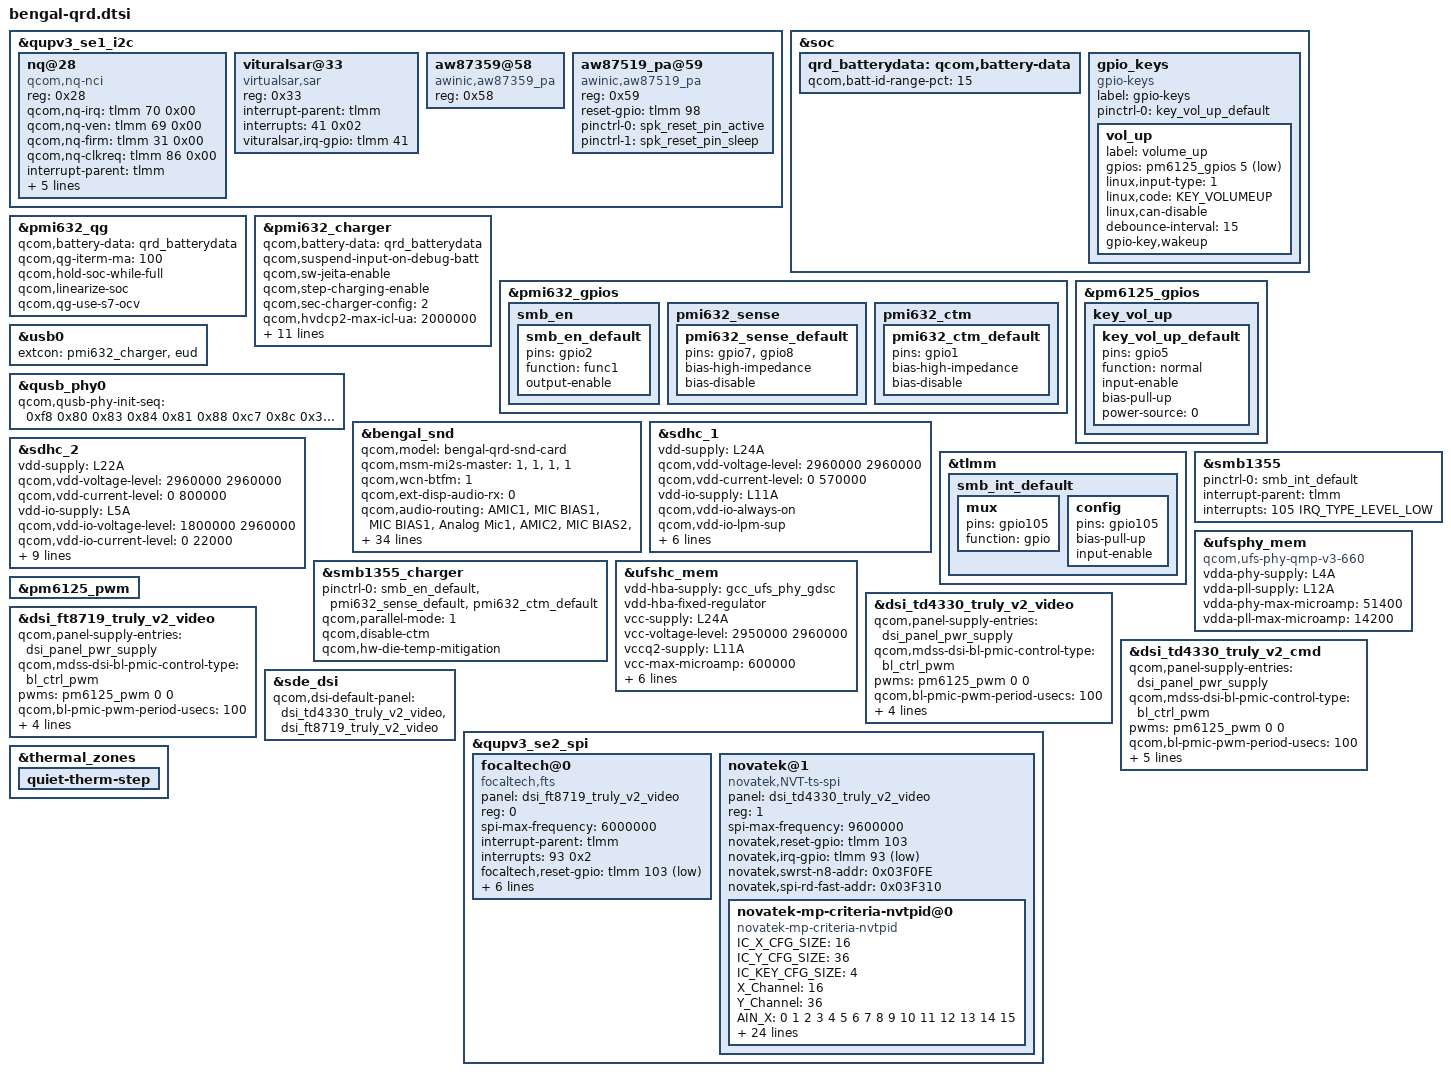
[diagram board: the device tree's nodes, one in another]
#include <dt-bindings/gpio/gpio.h>
#include <dt-bindings/iio/qcom,spmi-vadc.h>
#include <dt-bindings/input/input.h>
#include "bengal-thermal-overlay.dtsi"
#include "bengal-audio-overlay.dtsi"
#include "bengal-sde-display.dtsi"
#include "camera/bengal-camera-sensor-qrd.dtsi"

&qupv3_se1_i2c {
	status = "ok";
	#include "smb1355.dtsi"
};

&soc {
	qrd_batterydata: qcom,battery-data {
		qcom,batt-id-range-pct = <15>;
		#include "qg-batterydata-atl466271_3300mAh.dtsi"
	};
};

&pmi632_qg {
	qcom,battery-data = <&qrd_batterydata>;
	qcom,qg-iterm-ma = <100>;
	qcom,hold-soc-while-full;
	qcom,linearize-soc;
	qcom,qg-use-s7-ocv;
};

&pmi632_charger {
	qcom,battery-data = <&qrd_batterydata>;
	qcom,suspend-input-on-debug-batt;
	qcom,sw-jeita-enable;
	qcom,step-charging-enable;
	/* SMB1355 only */
	qcom,sec-charger-config = <2>;
	qcom,hvdcp2-max-icl-ua = <2000000>;
	dpdm-supply = <&qusb_phy0>;
	qcom,charger-temp-max = <800>;
	qcom,smb-temp-max = <800>;
	qcom,auto-recharge-soc = <98>;
	qcom,flash-disable-soc = <1>;
	qcom,hw-die-temp-mitigation;
	qcom,hw-connector-mitigation;
	qcom,connector-internal-pull-kohm = <100>;
	qcom,float-option = <1>;
	qcom,thermal-mitigation = <4200000 3500000 3000000
			2500000 2000000 1500000 1000000 500000>;
};

&pmi632_gpios {
	smb_en {
		smb_en_default: smb_en_default {
			pins = "gpio2";
			function = "func1";
			output-enable;
		};
	};

	pmi632_sense {
		/* GPIO 7 and 8 are external-sense pins for PMI632 */
		pmi632_sense_default: pmi632_sense_default {
			pins = "gpio7", "gpio8";
			bias-high-impedance;	/* disable the GPIO */
			bias-disable;		/* no-pull */
		};
	};

	pmi632_ctm {
		/* Disable GPIO1 for h/w base mitigation */
		pmi632_ctm_default: pmi632_ctm_default {
			pins = "gpio1";
			bias-high-impedance;	/* disable the GPIO */
			bias-disable;		/* no-pull */
		};
	};
};

&pm6125_gpios {
	key_vol_up {
		key_vol_up_default: key_vol_up_default {
			pins = "gpio5";
			function = "normal";
			input-enable;
			bias-pull-up;
			power-source = <0>;
		};
	};
};

&usb0 {
	extcon = <&pmi632_charger>, <&eud>;
};

&qusb_phy0 {
	qcom,qusb-phy-init-seq = <0xf8 0x80
				0x83 0x84
				0x81 0x88
				0xc7 0x8c
				0x30 0x08
				0x79 0x0c
				0x21 0x10
				0x14 0x9c
				0x80 0x04
				0x9f 0x1c
				0x00 0x18>;
};

&soc {
	gpio_keys {
		compatible = "gpio-keys";
		label = "gpio-keys";

		pinctrl-names = "default";
		pinctrl-0 = <&key_vol_up_default>;

		vol_up {
			label = "volume_up";
			gpios = <&pm6125_gpios 5 GPIO_ACTIVE_LOW>;
			linux,input-type = <1>;
			linux,code = <KEY_VOLUMEUP>;
			linux,can-disable;
			debounce-interval = <15>;
			gpio-key,wakeup;
		};
	};
};

&bengal_snd {
	qcom,model = "bengal-qrd-snd-card";
	qcom,msm-mi2s-master = <1>, <1>, <1>, <1>;
	qcom,wcn-btfm = <1>;
	qcom,ext-disp-audio-rx = <0>;
	qcom,audio-routing =
		"AMIC1", "MIC BIAS1",
		"MIC BIAS1", "Analog Mic1",
		"AMIC2", "MIC BIAS2",
		"MIC BIAS2", "Analog Mic2",
		"AMIC3", "MIC BIAS3",
		"MIC BIAS3", "Analog Mic3",
		"AMIC4", "MIC BIAS3",
		"MIC BIAS3", "Analog Mic4",
		"IN1_HPHL", "HPHL_OUT",
		"IN2_HPHR", "HPHR_OUT",
		"IN3_AUX", "AUX_OUT",
		"SpkrMono WSA_IN", "AUX",
		"TX SWR_MIC0", "ADC1_OUTPUT",
		"TX SWR_MIC4", "ADC2_OUTPUT",
		"TX SWR_MIC5", "ADC3_OUTPUT",
		"TX SWR_MIC0", "VA_TX_SWR_CLK",
		"TX SWR_MIC1", "VA_TX_SWR_CLK",
		"TX SWR_MIC2", "VA_TX_SWR_CLK",
		"TX SWR_MIC3", "VA_TX_SWR_CLK",
		"TX SWR_MIC4", "VA_TX_SWR_CLK",
		"TX SWR_MIC5", "VA_TX_SWR_CLK",
		"TX SWR_MIC6", "VA_TX_SWR_CLK",
		"TX SWR_MIC7", "VA_TX_SWR_CLK",
		"TX SWR_MIC8", "VA_TX_SWR_CLK",
		"TX SWR_MIC9", "VA_TX_SWR_CLK",
		"TX SWR_MIC10", "VA_TX_SWR_CLK",
		"TX SWR_MIC11", "VA_TX_SWR_CLK",
		"RX_TX DEC0_INP", "TX DEC0 MUX",
		"RX_TX DEC1_INP", "TX DEC1 MUX",
		"RX_TX DEC2_INP", "TX DEC2 MUX",
		"RX_TX DEC3_INP", "TX DEC3 MUX",
		"TX_AIF1 CAP", "VA_TX_SWR_CLK",
		"TX_AIF2 CAP", "VA_TX_SWR_CLK",
		"TX_AIF3 CAP", "VA_TX_SWR_CLK",
		"VA SWR_MIC0", "ADC1_OUTPUT",
		"VA SWR_MIC4", "ADC2_OUTPUT",
		"VA SWR_MIC5", "ADC3_OUTPUT";
	qcom,msm-mbhc-hphl-swh = <1>;
	qcom,msm-mbhc-gnd-swh = <1>;
	asoc-codec  = <&stub_codec>, <&bolero>;
	asoc-codec-names = "msm-stub-codec.1", "bolero_codec";
	qcom,wsa-max-devs = <0>;
	qcom,wsa-devs = <0>;
	qcom,wsa-aux-dev-prefix = "SpkrMono";
	qcom,codec-max-aux-devs = <1>;
	qcom,codec-aux-devs = <&wcd937x_codec>;
	qcom,msm_audio_ssr_devs = <&audio_apr>, <&q6core>, <&bolero>,
				<&lpi_tlmm>;
};

&qupv3_se1_i2c {
	status = "ok";
	#address-cells = <1>;
	#size-cells = <0>;
	nq@28 {
		compatible = "qcom,nq-nci";
		reg = <0x28>;
		qcom,nq-irq = <&tlmm 70 0x00>;
		qcom,nq-ven = <&tlmm 69 0x00>;
		qcom,nq-firm = <&tlmm 31 0x00>;
		qcom,nq-clkreq = <&tlmm 86 0x00>;
		interrupt-parent = <&tlmm>;
		interrupts = <70 0>;
		interrupt-names = "nfc_irq";
		pinctrl-names = "nfc_active", "nfc_suspend";
		pinctrl-0 = <&nfc_int_active &nfc_enable_active
				&nfc_clk_req_active>;
		pinctrl-1 = <&nfc_int_suspend &nfc_enable_suspend
				&nfc_clk_req_suspend>;
	};

	vituralsar@33{/*Add by HQ-102007757 for vituralsar*/
		compatible = "virtualsar,sar";
		reg = <0x33>;
		interrupt-parent = <&tlmm>;
		interrupts = <41 0x02>;
		vituralsar,irq-gpio = <&tlmm 41 0x2008>;
		status = "ok";
	};

	aw87359@58 {
		compatible = "awinic,aw87359_pa";
		reg = <0x58>;
		status = "okay";
	};

	aw87519_pa@59 {
		compatible = "awinic,aw87519_pa";
		reg = <0x59>;
		reset-gpio = <&tlmm 98 0>;
		pinctrl-names = "aw87519_pa_reset_active", "aw87519_pa_reset_sleep";
		pinctrl-0 = <&spk_reset_pin_active>;
		pinctrl-1 = <&spk_reset_pin_sleep>;
	};
};

&sdhc_1 {
	vdd-supply = <&L24A>;
	qcom,vdd-voltage-level = <2960000 2960000>;
	qcom,vdd-current-level = <0 570000>;

	vdd-io-supply = <&L11A>;
	qcom,vdd-io-always-on;
	qcom,vdd-io-lpm-sup;
	qcom,vdd-io-voltage-level = <1800000 1800000>;
	qcom,vdd-io-current-level = <0 325000>;

	pinctrl-names = "active", "sleep";
	pinctrl-0 = <&sdc1_clk_on &sdc1_cmd_on &sdc1_data_on
					&sdc1_rclk_on>;
	pinctrl-1 = <&sdc1_clk_off &sdc1_cmd_off &sdc1_data_off
					&sdc1_rclk_off>;

	status = "ok";
};

&sdhc_2 {
	vdd-supply = <&L22A>;
	qcom,vdd-voltage-level = <2960000 2960000>;
	qcom,vdd-current-level = <0 800000>;

	vdd-io-supply = <&L5A>;
	qcom,vdd-io-voltage-level = <1800000 2960000>;
	qcom,vdd-io-current-level = <0 22000>;

	vdd-io-bias-supply = <&L7A>;
	qcom,vdd-io-bias-voltage-level = <1256000 1256000>;
	qcom,vdd-io-bias-current-level = <0 6000>;

	pinctrl-names = "active", "sleep";
	pinctrl-0 = <&sdc2_clk_on  &sdc2_cmd_on &sdc2_data_on &sdc2_cd_on>;
	pinctrl-1 = <&sdc2_clk_off &sdc2_cmd_off &sdc2_data_off &sdc2_cd_off>;

	cd-gpios = <&tlmm 88 GPIO_ACTIVE_HIGH>;

	status = "ok";
};

&tlmm {
	smb_int_default: smb_int_default {
		mux {
			pins = "gpio105";
			function = "gpio";
		};

		config {
			pins = "gpio105";
			bias-pull-up;
			input-enable;
		};
	};
};

&smb1355 {
	pinctrl-names = "default";
	pinctrl-0 = <&smb_int_default>;
	interrupt-parent = <&tlmm>;
	interrupts = <105 IRQ_TYPE_LEVEL_LOW>;
	status = "ok";
};

&smb1355_charger {
	pinctrl-names = "default";
	pinctrl-0 = <&smb_en_default &pmi632_sense_default &pmi632_ctm_default>;
	qcom,parallel-mode = <1>;
	qcom,disable-ctm;
	qcom,hw-die-temp-mitigation;
	status = "ok";
};

&ufsphy_mem {
	compatible = "qcom,ufs-phy-qmp-v3-660";

	vdda-phy-supply = <&L4A>; /* 0.9v */
	vdda-pll-supply = <&L12A>; /* 1.8v */
	vdda-phy-max-microamp = <51400>;
	vdda-pll-max-microamp = <14200>;

	status = "ok";
};

&ufshc_mem {
	vdd-hba-supply = <&gcc_ufs_phy_gdsc>;
	vdd-hba-fixed-regulator;
	vcc-supply = <&L24A>;
	vcc-voltage-level = <2950000 2960000>;
	vccq2-supply = <&L11A>;
	vcc-max-microamp = <600000>;
	vccq2-max-microamp = <600000>;
	vccq2-pwr-collapse-sup;

	qcom,vddp-ref-clk-supply = <&L18A>;
	qcom,vddp-ref-clk-max-microamp = <100>;
	qcom,vddp-ref-clk-min-uV = <1232000>;
	qcom,vddp-ref-clk-max-uV = <1232000>;

	status = "ok";
};

&pm6125_pwm {
	status = "ok";
};

&dsi_td4330_truly_v2_video {
	qcom,panel-supply-entries = <&dsi_panel_pwr_supply>;
	qcom,mdss-dsi-bl-pmic-control-type = "bl_ctrl_pwm";
	pwms = <&pm6125_pwm 0 0>;
	qcom,bl-pmic-pwm-period-usecs = <100>;
	qcom,mdss-dsi-bl-min-level = <1>;
	qcom,mdss-dsi-bl-max-level = <4095>;
	qcom,platform-reset-gpio = <&tlmm 82 0>;
	qcom,platform-bklight-en-gpio = <&pmi632_gpios 6 0>;
};


&dsi_ft8719_truly_v2_video {
	qcom,panel-supply-entries = <&dsi_panel_pwr_supply>;
	qcom,mdss-dsi-bl-pmic-control-type = "bl_ctrl_pwm";
	pwms = <&pm6125_pwm 0 0>;
	qcom,bl-pmic-pwm-period-usecs = <100>;
	qcom,mdss-dsi-bl-min-level = <1>;
	qcom,mdss-dsi-bl-max-level = <4095>;
	qcom,platform-reset-gpio = <&tlmm 82 0>;
	qcom,platform-bklight-en-gpio = <&pmi632_gpios 6 0>;
};

&dsi_td4330_truly_v2_cmd {
	qcom,panel-supply-entries = <&dsi_panel_pwr_supply>;
	qcom,mdss-dsi-bl-pmic-control-type = "bl_ctrl_pwm";
	pwms = <&pm6125_pwm 0 0>;
	qcom,bl-pmic-pwm-period-usecs = <100>;
	qcom,mdss-dsi-bl-min-level = <1>;
	qcom,mdss-dsi-bl-max-level = <4095>;
	qcom,platform-te-gpio = <&tlmm 81 0>;
	qcom,platform-reset-gpio = <&tlmm 82 0>;
	qcom,platform-bklight-en-gpio = <&pmi632_gpios 6 0>;
};

&sde_dsi {
	qcom,dsi-default-panel = <&dsi_td4330_truly_v2_video &dsi_ft8719_truly_v2_video>;
};
/*
&qupv3_se2_i2c {
	status = "okay";
	qcom,i2c-touch-active="synaptics,tcm-i2c";

	synaptics_tcm@20 {
		compatible = "synaptics,tcm-i2c";
		reg = <0x20>;
		interrupt-parent = <&tlmm>;
		interrupts = <80 0x2008>;
		pinctrl-names = "pmx_ts_active","pmx_ts_suspend",
			"pmx_ts_release";
		pinctrl-0 = <&ts_int_active &ts_reset_active>;
		pinctrl-1 = <&ts_int_suspend &ts_reset_suspend>;
		pinctrl-2 = <&ts_release>;
		synaptics,irq-gpio = <&tlmm 80 0x2008>;
		synaptics,irq-on-state = <0>;
		synaptics,reset-gpio = <&tlmm 71 0x00>;
		synaptics,reset-on-state = <0>;
		synaptics,reset-active-ms = <20>;
		synaptics,reset-delay-ms = <200>;
		synaptics,power-delay-ms = <200>;
		synaptics,ubl-i2c-addr = <0x20>;
		synaptics,extend_report;
		synaptics,firmware-name = "synaptics_firmware_k.img";

		panel = <&dsi_td4330_truly_v2_video &dsi_td4330_truly_v2_cmd>;
	};
};*/


&qupv3_se2_spi {
	status = "okay";
	focaltech@0 { 
			compatible = "focaltech,fts";
			panel = <&dsi_ft8719_truly_v2_video>;
			reg = <0>;
			spi-max-frequency = <6000000>;
			interrupt-parent = <&tlmm>;
			interrupts = <93 0x2>;
			focaltech,reset-gpio = <&tlmm 103 0x01>;
			focaltech,irq-gpio = <&tlmm 93 0x02>;
			focaltech,max-touch-number = <10>;			
			focaltech,display-coords =  <0 0 1080 2340>;
			
			pinctrl-names = "pmx_ts_active","pmx_ts_suspend","pmx_ts_release";
			pinctrl-0 = <&ts_int_active &ts_reset_active>;
			pinctrl-1 = <&ts_int_suspend &ts_reset_suspend>;
			pinctrl-2 = <&ts_release>;
		};


	/* Novatek device tree node */
	novatek@1 {
		compatible = "novatek,NVT-ts-spi";
		panel = <&dsi_td4330_truly_v2_video>;
		reg = <1>; //Same as CS ID
		status = "ok";

		spi-max-frequency = <9600000>;	//4800000,9600000,15000000,19200000
		novatek,reset-gpio = <&tlmm 103 0x00>;
		novatek,irq-gpio = <&tlmm 93 0x2001>;

		/* 525 */
		//novatek,swrst-n8-addr = <0x01F01A>;

		/* 672A, 525B, 675, 526, 672C */
		novatek,swrst-n8-addr = <0x03F0FE>;
		novatek,spi-rd-fast-addr = <0x03F310>;

		/* MP */
		//novatek,mp-support-dt;

		novatek-mp-criteria-nvtpid@0 {
			#address-cells = <1>;
			#size-cells = <0>;
			compatible = "novatek-mp-criteria-nvtpid";

			/* MP Config */
			IC_X_CFG_SIZE = <16>;
			IC_Y_CFG_SIZE = <36>;
			IC_KEY_CFG_SIZE = <4>;
			X_Channel = <16>;
			Y_Channel = <36>;
			AIN_X = <0 1 2 3 4 5 6 7 8 9 10 11 12 13 14 15>;
			AIN_Y = <0 1 2 3 4 5 6 7 8 9 10 11 12 13 14 15 16 17
						18 19 20 21 22 23 24 25 26 27 28 29 30 31 32 33 34 35>;
			AIN_KEY = <0 1 2 0xFF>;

			/* MP Criteria */
			PS_Config_Lmt_Short_Rawdata_P = <
				14000	14000	14000	14000	14000	14000	14000	14000	14000	14000	14000	14000	14000	14000	14000	14000
				14000	14000	14000	14000	14000	14000	14000	14000	14000	14000	14000	14000	14000	14000	14000	14000
				14000	14000	14000	14000	14000	14000	14000	14000	14000	14000	14000	14000	14000	14000	14000	14000
				14000	14000	14000	14000	14000	14000	14000	14000	14000	14000	14000	14000	14000	14000	14000	14000
				14000	14000	14000	14000	14000	14000	14000	14000	14000	14000	14000	14000	14000	14000	14000	14000
				14000	14000	14000	14000	14000	14000	14000	14000	14000	14000	14000	14000	14000	14000	14000	14000
				14000	14000	14000	14000	14000	14000	14000	14000	14000	14000	14000	14000	14000	14000	14000	14000
				14000	14000	14000	14000	14000	14000	14000	14000	14000	14000	14000	14000	14000	14000	14000	14000
				14000	14000	14000	14000	14000	14000	14000	14000	14000	14000	14000	14000	14000	14000	14000	14000
				14000	14000	14000	14000	14000	14000	14000	14000	14000	14000	14000	14000	14000	14000	14000	14000
				14000	14000	14000	14000	14000	14000	14000	14000	14000	14000	14000	14000	14000	14000	14000	14000
				14000	14000	14000	14000	14000	14000	14000	14000	14000	14000	14000	14000	14000	14000	14000	14000
				14000	14000	14000	14000	14000	14000	14000	14000	14000	14000	14000	14000	14000	14000	14000	14000
				14000	14000	14000	14000	14000	14000	14000	14000	14000	14000	14000	14000	14000	14000	14000	14000
				14000	14000	14000	14000	14000	14000	14000	14000	14000	14000	14000	14000	14000	14000	14000	14000
				14000	14000	14000	14000	14000	14000	14000	14000	14000	14000	14000	14000	14000	14000	14000	14000
				14000	14000	14000	14000	14000	14000	14000	14000	14000	14000	14000	14000	14000	14000	14000	14000
				14000	14000	14000	14000	14000	14000	14000	14000	14000	14000	14000	14000	14000	14000	14000	14000
				14000	14000	14000	14000	14000	14000	14000	14000	14000	14000	14000	14000	14000	14000	14000	14000
				14000	14000	14000	14000	14000	14000	14000	14000	14000	14000	14000	14000	14000	14000	14000	14000
				14000	14000	14000	14000	14000	14000	14000	14000	14000	14000	14000	14000	14000	14000	14000	14000
				14000	14000	14000	14000	14000	14000	14000	14000	14000	14000	14000	14000	14000	14000	14000	14000
				14000	14000	14000	14000	14000	14000	14000	14000	14000	14000	14000	14000	14000	14000	14000	14000
				14000	14000	14000	14000	14000	14000	14000	14000	14000	14000	14000	14000	14000	14000	14000	14000
				14000	14000	14000	14000	14000	14000	14000	14000	14000	14000	14000	14000	14000	14000	14000	14000
				14000	14000	14000	14000	14000	14000	14000	14000	14000	14000	14000	14000	14000	14000	14000	14000
				14000	14000	14000	14000	14000	14000	14000	14000	14000	14000	14000	14000	14000	14000	14000	14000
				14000	14000	14000	14000	14000	14000	14000	14000	14000	14000	14000	14000	14000	14000	14000	14000
				14000	14000	14000	14000	14000	14000	14000	14000	14000	14000	14000	14000	14000	14000	14000	14000
				14000	14000	14000	14000	14000	14000	14000	14000	14000	14000	14000	14000	14000	14000	14000	14000
				14000	14000	14000	14000	14000	14000	14000	14000	14000	14000	14000	14000	14000	14000	14000	14000
				14000	14000	14000	14000	14000	14000	14000	14000	14000	14000	14000	14000	14000	14000	14000	14000
				14000	14000	14000	14000	14000	14000	14000	14000	14000	14000	14000	14000	14000	14000	14000	14000
				14000	14000	14000	14000	14000	14000	14000	14000	14000	14000	14000	14000	14000	14000	14000	14000
				14000	14000	14000	14000	14000	14000	14000	14000	14000	14000	14000	14000	14000	14000	14000	14000
				14000	14000	14000	14000	14000	14000	14000	14000	14000	14000	14000	14000	14000	14000	14000	14000
				14008 14008 14008>;

			PS_Config_Lmt_Short_Rawdata_N = <
				11300	11300	11300	11300	11300	11300	11300	11300	11300	11300	11300	11300	11300	11300	11300	11300
				11300	11300	11300	11300	11300	11300	11300	11300	11300	11300	11300	11300	11300	11300	11300	11300
				11300	11300	11300	11300	11300	11300	11300	11300	11300	11300	11300	11300	11300	11300	11300	11300
				11300	11300	11300	11300	11300	11300	11300	11300	11300	11300	11300	11300	11300	11300	11300	11300
				11300	11300	11300	11300	11300	11300	11300	11300	11300	11300	11300	11300	11300	11300	11300	11300
				11300	11300	11300	11300	11300	11300	11300	11300	11300	11300	11300	11300	11300	11300	11300	11300
				11300	11300	11300	11300	11300	11300	11300	11300	11300	11300	11300	11300	11300	11300	11300	11300
				11300	11300	11300	11300	11300	11300	11300	11300	11300	11300	11300	11300	11300	11300	11300	11300
				11300	11300	11300	11300	11300	11300	11300	11300	11300	11300	11300	11300	11300	11300	11300	11300
				11300	11300	11300	11300	11300	11300	11300	11300	11300	11300	11300	11300	11300	11300	11300	11300
				11300	11300	11300	11300	11300	11300	11300	11300	11300	11300	11300	11300	11300	11300	11300	11300
				11300	11300	11300	11300	11300	11300	11300	11300	11300	11300	11300	11300	11300	11300	11300	11300
				11300	11300	11300	11300	11300	11300	11300	11300	11300	11300	11300	11300	11300	11300	11300	11300
				11300	11300	11300	11300	11300	11300	11300	11300	11300	11300	11300	11300	11300	11300	11300	11300
				11300	11300	11300	11300	11300	11300	11300	11300	11300	11300	11300	11300	11300	11300	11300	11300
				11300	11300	11300	11300	11300	11300	11300	11300	11300	11300	11300	11300	11300	11300	11300	11300
				11300	11300	11300	11300	11300	11300	11300	11300	11300	11300	11300	11300	11300	11300	11300	11300
				11300	11300	11300	11300	11300	11300	11300	11300	11300	11300	11300	11300	11300	11300	11300	11300
				11300	11300	11300	11300	11300	11300	11300	11300	11300	11300	11300	11300	11300	11300	11300	11300
				11300	11300	11300	11300	11300	11300	11300	11300	11300	11300	11300	11300	11300	11300	11300	11300
				11300	11300	11300	11300	11300	11300	11300	11300	11300	11300	11300	11300	11300	11300	11300	11300
				11300	11300	11300	11300	11300	11300	11300	11300	11300	11300	11300	11300	11300	11300	11300	11300
				11300	11300	11300	11300	11300	11300	11300	11300	11300	11300	11300	11300	11300	11300	11300	11300
				11300	11300	11300	11300	11300	11300	11300	11300	11300	11300	11300	11300	11300	11300	11300	11300
				11300	11300	11300	11300	11300	11300	11300	11300	11300	11300	11300	11300	11300	11300	11300	11300
				11300	11300	11300	11300	11300	11300	11300	11300	11300	11300	11300	11300	11300	11300	11300	11300
				11300	11300	11300	11300	11300	11300	11300	11300	11300	11300	11300	11300	11300	11300	11300	11300
				11300	11300	11300	11300	11300	11300	11300	11300	11300	11300	11300	11300	11300	11300	11300	11300
				11300	11300	11300	11300	11300	11300	11300	11300	11300	11300	11300	11300	11300	11300	11300	11300
				11300	11300	11300	11300	11300	11300	11300	11300	11300	11300	11300	11300	11300	11300	11300	11300
				11300	11300	11300	11300	11300	11300	11300	11300	11300	11300	11300	11300	11300	11300	11300	11300
				11300	11300	11300	11300	11300	11300	11300	11300	11300	11300	11300	11300	11300	11300	11300	11300
				11300	11300	11300	11300	11300	11300	11300	11300	11300	11300	11300	11300	11300	11300	11300	11300
				11300	11300	11300	11300	11300	11300	11300	11300	11300	11300	11300	11300	11300	11300	11300	11300
				11300	11300	11300	11300	11300	11300	11300	11300	11300	11300	11300	11300	11300	11300	11300	11300
				11300	11300	11300	11300	11300	11300	11300	11300	11300	11300	11300	11300	11300	11300	11300	11300
				10000 10000 10000>;

			PS_Config_Lmt_Open_Rawdata_P = <
				2712	4204	4217	4272	4224	4255	3641	65535	65535	3700	4265	4324	4292	4372	4271	2824
				4152	4251	4193	4249	4201	4235	4185	4338	4290	4279	4240	4288	4260	4337	4307	4304
				4262	4276	4216	4271	4220	4259	4206	4232	4227	4298	4258	4306	4282	4356	4321	4371
				4241	4288	4231	4286	4230	4273	4217	4244	4245	4312	4277	4323	4302	4371	4338	4372
				4263	4274	4221	4276	4217	4258	4202	4227	4235	4305	4272	4316	4297	4366	4329	4382
				4269	4300	4248	4298	4239	4282	4222	4249	4244	4311	4282	4324	4305	4371	4335	4373
				4255	4304	4250	4300	4243	4284	4222	4249	4258	4320	4293	4337	4312	4378	4345	4377
				4274	4319	4263	4310	4250	4297	4234	4259	4251	4311	4286	4334	4309	4372	4339	4386
				4278	4311	4259	4305	4246	4291	4227	4253	4262	4320	4297	4342	4316	4378	4347	4377
				4287	4330	4276	4324	4267	4311	4244	4273	4284	4331	4295	4358	4329	4389	4358	4380
				4276	4316	4264	4307	4248	4295	4227	4260	4283	4331	4295	4358	4333	4391	4356	4389
				4290	4319	4268	4310	4250	4296	4229	4260	4284	4330	4296	4358	4329	4389	4352	4385
				4272	4324	4273	4314	4255	4302	4235	4265	4293	4340	4307	4370	4338	4399	4361	4373
				4269	4325	4277	4318	4262	4307	4237	4277	4291	4339	4309	4371	4335	4394	4354	4394
				4269	4318	4278	4318	4257	4302	4235	4279	4287	4335	4301	4361	4326	4386	4343	4390
				4272	4312	4269	4309	4248	4295	4232	4274	4312	4358	4325	4384	4345	4408	4361	4358
				4268	4300	4258	4300	4240	4286	4222	4278	4307	4358	4325	4385	4347	4409	4357	4366
				4258	4301	4260	4300	4239	4283	4220	4272	4278	4324	4293	4353	4314	4376	4324	4367
				4245	4302	4258	4297	4237	4283	4222	4276	4282	4329	4300	4361	4319	4378	4328	4351
				4237	4287	4241	4283	4224	4272	4211	4262	4283	4326	4298	4357	4312	4371	4318	4354
				4236	4282	4234	4277	4216	4264	4204	4254	4260	4311	4279	4338	4296	4354	4296	4364
				4222	4284	4236	4278	4217	4268	4211	4258	4263	4318	4284	4343	4298	4358	4298	4345
				4215	4264	4217	4258	4196	4245	4189	4239	4271	4328	4292	4349	4302	4363	4310	4323
				4220	4260	4212	4254	4191	4240	4185	4239	4250	4311	4273	4328	4283	4344	4291	4306
				4198	4240	4193	4240	4177	4229	4173	4224	4235	4295	4254	4309	4263	4320	4267	4306
				4197	4230	4183	4229	4165	4216	4164	4212	4222	4282	4243	4297	4251	4306	4254	4297
				4175	4221	4169	4212	4152	4207	4156	4208	4213	4279	4235	4288	4245	4298	4249	4271
				4165	4208	4157	4202	4141	4199	4142	4194	4207	4272	4227	4281	4237	4290	4237	4263
				4155	4194	4142	4187	4126	4182	4128	4180	4180	4243	4197	4249	4207	4259	4211	4251
				4144	4175	4124	4170	4109	4168	4113	4164	4169	4232	4185	4240	4199	4250	4203	4232
				4130	4156	4103	4147	4090	4146	4093	4145	4156	4218	4170	4224	4183	4236	4191	4211
				3803	4146	3787	4137	3776	4137	3782	4136	3829	4202	3841	4210	3854	4217	3859	4203
				3787	3827	3775	3821	3761	3813	3766	3818	3808	3864	3821	3877	3836	3887	3845	3897
				3778	3811	3763	3807	3749	3801	3757	3808	3802	3856	3813	3870	3830	3881	3840	3915
				3677	3771	3722	3770	3712	3764	3719	3771	3782	3834	3792	3849	3808	3859	3818	3796
				2246	3721	3733	3785	3728	3778	3733	3788	3787	3836	3794	3855	3815	3865	3765	2343
				5120 5120 5120>;

			PS_Config_Lmt_Open_Rawdata_N = <
				1559	2417	2424	2455	2427	2446	2092	(-65535)	(-65535)	2127	2452	2485	2467	2513	2454	1623
				2387	2444	2410	2442	2414	2434	2406	2493	2465	2460	2437	2465	2449	2492	2476	2473
				2449	2457	2423	2454	2425	2448	2417	2433	2430	2471	2447	2475	2461	2503	2484	2512
				2438	2465	2432	2463	2431	2456	2424	2439	2440	2479	2458	2484	2473	2512	2493	2513
				2450	2457	2426	2457	2424	2447	2415	2430	2434	2474	2455	2481	2470	2509	2488	2519
				2454	2471	2441	2471	2436	2461	2427	2442	2439	2478	2461	2485	2474	2512	2492	2514
				2446	2473	2443	2471	2438	2463	2427	2442	2447	2483	2468	2492	2479	2517	2498	2516
				2457	2482	2450	2477	2443	2470	2433	2448	2444	2478	2463	2491	2476	2513	2494	2521
				2459	2478	2448	2474	2441	2466	2430	2444	2449	2483	2470	2495	2481	2517	2498	2516
				2464	2489	2457	2485	2452	2478	2439	2456	2463	2490	2468	2505	2488	2522	2505	2517
				2457	2481	2451	2476	2441	2468	2430	2449	2462	2490	2468	2505	2490	2524	2503	2522
				2465	2482	2453	2477	2443	2469	2430	2449	2463	2489	2469	2505	2488	2522	2501	2520
				2455	2485	2456	2479	2446	2473	2434	2452	2468	2495	2476	2511	2493	2528	2506	2514
				2454	2486	2458	2482	2449	2476	2436	2458	2466	2494	2476	2512	2492	2525	2503	2525
				2454	2482	2459	2482	2446	2473	2434	2460	2464	2492	2472	2506	2487	2521	2496	2523
				2455	2479	2454	2476	2441	2468	2433	2457	2479	2505	2486	2519	2498	2533	2506	2505
				2453	2471	2447	2471	2437	2463	2427	2459	2476	2505	2486	2520	2498	2534	2504	2509
				2447	2472	2449	2471	2436	2462	2425	2455	2459	2485	2468	2502	2479	2515	2485	2510
				2440	2473	2447	2470	2436	2462	2427	2457	2461	2488	2471	2506	2482	2517	2487	2500
				2436	2464	2438	2462	2427	2455	2420	2449	2462	2487	2471	2504	2479	2512	2482	2503
				2435	2461	2433	2458	2423	2451	2417	2445	2449	2478	2460	2493	2469	2503	2469	2509
				2427	2463	2435	2459	2424	2453	2420	2447	2450	2482	2463	2496	2471	2505	2471	2498
				2422	2451	2424	2447	2411	2440	2408	2436	2454	2487	2467	2500	2473	2508	2477	2484
				2425	2449	2421	2445	2409	2437	2406	2436	2443	2478	2456	2487	2462	2497	2466	2475
				2413	2437	2410	2437	2400	2430	2398	2427	2434	2468	2445	2476	2450	2483	2452	2475
				2412	2431	2404	2430	2394	2423	2393	2421	2427	2461	2438	2470	2444	2475	2445	2470
				2400	2426	2396	2421	2387	2418	2389	2419	2422	2460	2434	2465	2440	2471	2442	2454
				2394	2419	2390	2415	2380	2414	2381	2411	2418	2455	2430	2460	2436	2465	2436	2450
				2388	2411	2381	2406	2371	2403	2373	2403	2403	2438	2412	2442	2418	2448	2420	2444
				2381	2400	2371	2397	2362	2395	2364	2393	2396	2433	2406	2437	2414	2443	2416	2433
				2373	2389	2358	2384	2351	2383	2352	2382	2389	2425	2397	2427	2404	2435	2409	2420
				2186	2383	2176	2378	2171	2378	2173	2377	2200	2415	2208	2419	2215	2424	2218	2416
				2176	2200	2170	2196	2162	2192	2165	2195	2189	2221	2196	2228	2205	2234	2210	2240
				2171	2190	2162	2188	2154	2184	2160	2189	2185	2217	2192	2225	2201	2230	2207	2250
				2114	2168	2139	2167	2133	2163	2138	2168	2173	2203	2179	2212	2189	2218	2195	2181
				1291	2138	2146	2176	2143	2171	2146	2177	2176	2205	2181	2216	2192	2222	2164	1346
				(-511) (-511) (-511)>;

			PS_Config_Lmt_FW_Rawdata_P = <
				2030	2076	2083	2067	2072	2052	2056	65535	65535	2061	2057	2059	2067	2057	2064	2070
				2054	2052	2033	2103	2067	2029	2018	2100	2073	2051	2034	2067	2055	2090	2064	2022
				2069	2082	2060	2067	2057	2052	2046	2044	2056	2057	2052	2043	2081	2063	2063	2044
				2011	2085	2054	2085	2061	2048	2059	2064	2043	2096	2044	2051	2057	2087	2069	2015
				2072	2065	2051	2080	2056	2073	2063	2055	2085	2064	2064	2072	2047	2065	2078	2041
				2037	2089	2073	2072	2054	2044	2046	2055	2091	2047	2067	2083	2046	2076	2077	2028
				2047	2067	2100	2070	2042	2077	2091	2096	2060	2076	2052	2074	2061	2069	2068	2039
				2047	2069	2070	2076	2070	2055	2057	2065	2067	2072	2063	2070	2059	2068	2093	2055
				2044	2077	2029	2063	2048	2021	2051	2033	2100	2037	2072	2083	2024	2087	2094	2052
				2038	2054	2086	2099	2042	2080	2055	2047	2065	2063	2077	2061	2080	2067	2057	2054
				2048	2055	2074	2067	2048	2064	2041	2038	2054	2061	2076	2069	2064	2051	2052	2035
				2057	2065	2069	2082	2050	2055	2047	2048	2093	2087	2043	2054	2068	2089	2083	2037
				2051	2089	2089	2044	2091	2072	2090	2033	2072	2063	2059	2063	2060	2072	2091	2042
				2048	2056	2039	2070	2065	2059	2070	2042	2063	2073	2080	2064	2107	2012	2056	2043
				2077	2069	2064	2051	2059	2067	2057	2087	2083	2076	2063	2061	2073	2047	2042	2047
				2048	2076	2072	2065	2063	2072	2091	2077	2090	2125	2072	2064	2107	2013	2039	2051
				2083	2113	2037	2008	2086	2093	2107	2060	2106	2072	2029	2046	2082	2082	2052	2042
				2060	2073	2076	2069	2073	2070	2081	2067	2043	2055	2106	2093	2042	2069	2108	2035
				2039	2033	2116	2044	2093	2072	2016	2055	2037	2063	2076	2083	2051	2069	2095	2052
				2046	2106	2068	2050	2106	2087	2068	2061	2042	2078	2046	2060	2082	2060	2072	2057
				2095	2044	2094	2054	2039	2065	2048	2047	2059	2047	2074	2050	2069	2086	2064	2068
				2052	2041	2061	2094	2043	2067	2072	2078	2034	2115	2093	2095	2073	2034	2060	2035
				2029	2087	2034	2046	2067	2104	2068	2028	2068	2081	2073	2069	2056	2056	2073	2048
				2018	2063	2026	2087	2068	2081	2095	2033	2055	2096	2070	2099	2055	2048	2081	2077
				2037	2067	2070	2060	2064	2059	2069	2081	2077	2067	2059	2064	2069	2070	2089	2057
				2059	2076	2103	2076	2069	2028	2081	2077	2044	2041	2061	2054	2073	2082	2037	2059
				2064	2063	2069	2024	2086	2056	2028	2069	2077	2054	2061	2056	2054	2093	2064	2025
				2078	2047	2035	2096	2059	2104	2100	2070	2057	2076	2051	2068	2082	2063	2076	2070
				2029	2065	2069	2078	2070	2069	2070	2068	2043	2073	2035	2091	2055	2054	2074	2074
				2025	2043	2065	2081	2068	2057	2090	2057	2067	2072	2068	2081	2034	2082	2015	2082
				2047	2072	2048	2047	2076	2099	2089	2073	2093	2089	2083	2093	2056	2094	2041	2039
				2022	2090	2048	2059	2060	2083	2068	2083	2082	2057	2074	2083	2067	2044	2051	2047
				2055	2072	2063	2060	2057	2072	2063	2081	2078	2089	2089	2061	2067	2086	2055	2048
				2057	2086	2099	2080	2054	2026	2074	2031	2026	2034	2047	2093	2116	2046	2042	2091
				2068	2048	2042	2106	2028	2059	2083	2069	2063	2052	2054	2087	2048	2091	2033	2037
				2067	2063	2072	2072	2050	2080	2073	2051	2017	2085	2087	2050	2028	2106	2098	2082
				2560 2560 2560>;

			PS_Config_Lmt_FW_Rawdata_N = <
				1093	1117	1122	1113	1115	1105	1107	(-65535)	(-65535)	1110	1108	1108	1113	1108	1111	1115
				1106	1105	1094	1132	1113	1092	1087	1131	1116	1104	1095	1113	1106	1125	1111	1089
				1114	1121	1109	1113	1108	1105	1101	1101	1107	1108	1105	1100	1120	1110	1110	1101
				1082	1122	1106	1122	1110	1103	1108	1111	1100	1129	1101	1104	1108	1124	1114	1085
				1115	1112	1104	1120	1107	1116	1110	1106	1122	1111	1111	1115	1102	1112	1119	1099
				1096	1124	1116	1115	1106	1101	1101	1106	1126	1102	1113	1122	1101	1117	1118	1092
				1102	1113	1131	1115	1099	1118	1126	1129	1109	1117	1105	1117	1110	1114	1113	1098
				1102	1114	1115	1117	1115	1106	1108	1112	1113	1115	1110	1115	1108	1113	1127	1106
				1101	1118	1092	1110	1103	1088	1104	1094	1131	1096	1115	1122	1089	1124	1127	1105
				1097	1106	1123	1130	1099	1120	1106	1102	1112	1110	1118	1110	1120	1113	1108	1106
				1103	1106	1117	1113	1103	1111	1099	1097	1106	1110	1117	1114	1111	1104	1105	1096
				1108	1112	1114	1121	1103	1106	1102	1103	1127	1124	1100	1106	1113	1124	1122	1096
				1104	1124	1124	1101	1126	1115	1125	1094	1115	1110	1108	1110	1109	1115	1126	1099
				1103	1107	1098	1115	1112	1108	1115	1099	1110	1116	1120	1111	1134	1083	1107	1100
				1118	1114	1111	1104	1108	1113	1108	1124	1122	1117	1110	1110	1116	1102	1099	1102
				1103	1117	1115	1112	1110	1115	1126	1118	1125	1144	1115	1111	1134	1084	1098	1104
				1122	1138	1096	1081	1123	1127	1134	1109	1134	1115	1092	1101	1121	1121	1105	1099
				1109	1116	1117	1114	1116	1115	1120	1113	1100	1106	1134	1127	1099	1114	1135	1096
				1098	1094	1139	1101	1127	1115	1085	1106	1096	1110	1117	1122	1104	1114	1128	1105
				1101	1134	1113	1103	1134	1124	1113	1110	1099	1119	1101	1109	1121	1109	1115	1108
				1128	1101	1127	1106	1098	1112	1103	1102	1108	1102	1117	1103	1114	1123	1111	1113
				1105	1099	1110	1127	1100	1113	1115	1119	1095	1138	1127	1128	1116	1095	1109	1096
				1092	1124	1095	1101	1113	1133	1113	1092	1113	1120	1116	1114	1107	1107	1116	1103
				1087	1110	1091	1124	1113	1120	1128	1094	1106	1129	1115	1130	1106	1103	1120	1118
				1096	1113	1115	1109	1111	1108	1114	1120	1118	1113	1108	1111	1114	1115	1124	1108
				1108	1117	1132	1117	1114	1092	1120	1118	1101	1099	1110	1106	1116	1121	1096	1108
				1111	1110	1114	1089	1123	1107	1092	1114	1118	1106	1110	1107	1106	1127	1111	1090
				1119	1102	1096	1129	1108	1133	1131	1115	1108	1117	1104	1113	1121	1110	1117	1115
				1092	1112	1114	1119	1115	1114	1115	1113	1100	1116	1096	1126	1106	1106	1117	1117
				1090	1100	1112	1120	1113	1108	1125	1108	1113	1115	1113	1120	1095	1121	1085	1121
				1102	1115	1103	1102	1117	1130	1124	1116	1127	1124	1122	1127	1107	1127	1099	1098
				1089	1125	1103	1108	1109	1122	1113	1122	1121	1108	1117	1122	1113	1101	1104	1102
				1106	1115	1110	1109	1108	1115	1110	1120	1119	1124	1124	1110	1113	1123	1106	1103
				1108	1123	1130	1120	1106	1091	1117	1094	1091	1095	1102	1127	1139	1101	1099	1126
				1113	1103	1099	1134	1092	1108	1122	1114	1110	1105	1106	1124	1103	1126	1094	1096
				1113	1110	1115	1115	1103	1120	1116	1104	1086	1122	1124	1103	1092	1134	1129	1121
				240 240 240>;

			PS_Config_Lmt_FW_CC_P = <
				112	125	122	122	120	120	117	65535	65535	124	122	122	122	124	124	111
				126	114	112	111	110	110	110	110	115	114	110	110	111	112	112	115
				135	112	111	110	109	109	107	109	112	112	110	110	110	111	111	115
				122	112	112	110	110	110	109	110	112	111	110	110	111	111	112	117
				120	112	111	110	110	109	109	109	112	111	110	110	111	112	112	115
				120	114	112	111	110	110	110	110	114	112	112	111	112	112	114	116
				120	112	110	110	109	107	107	107	112	111	110	110	110	111	112	116
				120	112	111	110	110	109	109	109	112	112	111	110	111	112	112	117
				117	112	111	110	109	109	110	109	112	111	110	110	111	112	112	115
				119	114	112	112	111	110	111	111	115	112	112	112	112	112	114	115
				117	111	110	110	109	107	109	109	111	111	110	110	110	111	111	116
				120	112	111	111	110	110	110	110	111	110	110	110	110	111	112	119
				116	111	110	110	109	107	109	110	111	111	110	110	111	111	112	115
				117	114	112	112	111	111	111	112	112	112	112	112	112	114	114	117
				116	111	110	110	109	109	109	110	110	110	110	110	110	111	112	117
				119	112	111	111	110	110	110	112	112	111	111	111	111	112	114	119
				115	111	111	110	109	109	110	111	112	111	111	111	112	112	112	115
				117	112	112	111	110	110	110	111	112	112	111	111	112	114	114	119
				116	111	110	109	107	107	109	109	110	110	109	109	110	111	111	117
				117	112	112	111	110	110	110	111	114	111	111	111	111	112	112	120
				115	112	111	110	110	110	110	110	112	111	110	110	111	112	112	117
				116	114	112	112	111	112	112	112	114	112	112	112	112	114	114	119
				116	111	110	110	109	109	110	110	112	111	110	110	111	112	112	119
				117	112	112	110	110	110	110	112	112	110	110	110	111	112	112	121
				115	112	111	110	110	110	110	111	111	111	110	111	111	112	112	120
				116	114	112	112	111	112	112	114	112	112	112	112	112	115	115	121
				115	112	112	111	110	110	111	112	111	112	111	112	112	112	115	121
				117	114	114	112	111	111	112	115	112	112	112	112	114	115	115	122
				116	112	111	111	110	111	111	112	111	112	111	112	112	114	115	121
				119	115	115	114	112	114	114	115	112	112	112	114	115	115	116	122
				116	112	111	111	110	110	110	112	111	111	110	111	112	114	115	122
				119	114	112	112	111	111	112	114	111	112	111	112	114	115	115	125
				115	114	112	112	111	112	112	115	111	111	111	112	112	114	115	122
				116	115	115	114	112	114	115	116	112	112	112	114	115	115	117	137
				115	112	111	110	110	110	112	112	110	110	111	111	112	114	115	115
				112	125	122	122	122	124	126	127	125	122	122	124	124	125	127	120
				314 314 314>;

			PS_Config_Lmt_FW_CC_N = <
				69	76	75	75	73	73	72	(-65535)	(-65535)	76	75	75	75	76	76	68
				77	69	69	68	67	67	67	67	70	69	67	67	68	69	69	70
				82	69	68	67	66	66	66	66	69	69	67	67	67	68	68	70
				75	69	69	67	67	67	66	67	69	68	67	67	68	68	69	72
				73	69	68	67	67	66	66	66	69	68	67	67	68	69	69	70
				73	69	69	68	67	67	67	67	69	69	69	68	69	69	69	71
				73	69	67	67	66	66	66	66	69	68	67	67	67	68	69	71
				73	69	68	67	67	66	66	66	69	69	68	67	68	69	69	72
				72	69	68	67	66	66	67	66	69	68	67	67	68	69	69	70
				72	69	69	69	68	67	68	68	70	69	69	69	69	69	69	70
				72	68	67	67	66	66	66	66	68	68	67	67	67	68	68	71
				73	69	68	68	67	67	67	67	68	67	67	67	67	68	69	72
				71	68	67	67	66	66	66	67	68	68	67	67	68	68	69	70
				72	69	69	69	68	68	68	69	69	69	69	69	69	69	69	72
				71	68	67	67	66	66	66	67	67	67	67	67	67	68	69	72
				72	69	68	68	67	67	67	69	69	68	68	68	68	69	69	72
				70	68	68	67	66	66	67	68	69	68	68	68	69	69	69	70
				72	69	69	68	67	67	67	68	69	69	68	68	69	69	69	72
				71	68	67	66	66	66	66	66	67	67	66	66	67	68	68	72
				72	69	69	68	67	67	67	68	69	68	68	68	68	69	69	73
				70	69	68	67	67	67	67	67	69	68	67	67	68	69	69	72
				71	69	69	69	68	69	69	69	69	69	69	69	69	69	69	72
				71	68	67	67	66	66	67	67	69	68	67	67	68	69	69	72
				72	69	69	67	67	67	67	69	69	67	67	67	68	69	69	74
				70	69	68	67	67	67	67	68	68	68	67	68	68	69	69	73
				71	69	69	69	68	69	69	69	69	69	69	69	69	70	70	74
				70	69	69	68	67	67	68	69	68	69	68	69	69	69	70	74
				72	69	69	69	68	68	69	70	69	69	69	69	69	70	70	75
				71	69	68	68	67	68	68	69	68	69	68	69	69	69	70	74
				72	70	70	69	69	69	69	70	69	69	69	69	70	70	71	75
				71	69	68	68	67	67	67	69	68	68	67	68	69	69	70	75
				72	69	69	69	68	68	69	69	68	69	68	69	69	70	70	76
				70	69	69	69	68	69	69	70	68	68	68	69	69	69	70	75
				71	70	70	69	69	69	70	71	69	69	69	69	70	70	72	84
				70	69	68	67	67	67	69	69	67	67	68	68	69	69	70	70
				69	76	75	75	75	76	77	78	76	75	75	76	76	76	78	73
				0 0 0>;

			PS_Config_Lmt_FW_Diff_P = <
				50	50	50	50	50	50	50	65535	65535	50	50	50	50	50	50	50
				50	50	50	50	50	50	50	50	50	50	50	50	50	50	50	50
				50	50	50	50	50	50	50	50	50	50	50	50	50	50	50	50
				50	50	50	50	50	50	50	50	50	50	50	50	50	50	50	50
				50	50	50	50	50	50	50	50	50	50	50	50	50	50	50	50
				50	50	50	50	50	50	50	50	50	50	50	50	50	50	50	50
				50	50	50	50	50	50	50	50	50	50	50	50	50	50	50	50
				50	50	50	50	50	50	50	50	50	50	50	50	50	50	50	50
				50	50	50	50	50	50	50	50	50	50	50	50	50	50	50	50
				50	50	50	50	50	50	50	50	50	50	50	50	50	50	50	50
				50	50	50	50	50	50	50	50	50	50	50	50	50	50	50	50
				50	50	50	50	50	50	50	50	50	50	50	50	50	50	50	50
				50	50	50	50	50	50	50	50	50	50	50	50	50	50	50	50
				50	50	50	50	50	50	50	50	50	50	50	50	50	50	50	50
				50	50	50	50	50	50	50	50	50	50	50	50	50	50	50	50
				50	50	50	50	50	50	50	50	50	50	50	50	50	50	50	50
				50	50	50	50	50	50	50	50	50	50	50	50	50	50	50	50
				50	50	50	50	50	50	50	50	50	50	50	50	50	50	50	50
				50	50	50	50	50	50	50	50	50	50	50	50	50	50	50	50
				50	50	50	50	50	50	50	50	50	50	50	50	50	50	50	50
				50	50	50	50	50	50	50	50	50	50	50	50	50	50	50	50
				50	50	50	50	50	50	50	50	50	50	50	50	50	50	50	50
				50	50	50	50	50	50	50	50	50	50	50	50	50	50	50	50
				50	50	50	50	50	50	50	50	50	50	50	50	50	50	50	50
				50	50	50	50	50	50	50	50	50	50	50	50	50	50	50	50
				50	50	50	50	50	50	50	50	50	50	50	50	50	50	50	50
				50	50	50	50	50	50	50	50	50	50	50	50	50	50	50	50
				50	50	50	50	50	50	50	50	50	50	50	50	50	50	50	50
				50	50	50	50	50	50	50	50	50	50	50	50	50	50	50	50
				50	50	50	50	50	50	50	50	50	50	50	50	50	50	50	50
				50	50	50	50	50	50	50	50	50	50	50	50	50	50	50	50
				50	50	50	50	50	50	50	50	50	50	50	50	50	50	50	50
				50	50	50	50	50	50	50	50	50	50	50	50	50	50	50	50
				50	50	50	50	50	50	50	50	50	50	50	50	50	50	50	50
				50	50	50	50	50	50	50	50	50	50	50	50	50	50	50	50
				50	50	50	50	50	50	50	50	50	50	50	50	50	50	50	50
				75 75 75>;

			PS_Config_Lmt_FW_Diff_N = <
				(-50)	(-50)	(-50)	(-50)	(-50)	(-50)	(-50)	(-65535)	(-65535)	(-50)	(-50)	(-50)	(-50)	(-50)	(-50)	(-50)
				(-50)	(-50)	(-50)	(-50)	(-50)	(-50)	(-50)	(-50)	(-50)	(-50)	(-50)	(-50)	(-50)	(-50)	(-50)	(-50)
				(-50)	(-50)	(-50)	(-50)	(-50)	(-50)	(-50)	(-50)	(-50)	(-50)	(-50)	(-50)	(-50)	(-50)	(-50)	(-50)
				(-50)	(-50)	(-50)	(-50)	(-50)	(-50)	(-50)	(-50)	(-50)	(-50)	(-50)	(-50)	(-50)	(-50)	(-50)	(-50)
				(-50)	(-50)	(-50)	(-50)	(-50)	(-50)	(-50)	(-50)	(-50)	(-50)	(-50)	(-50)	(-50)	(-50)	(-50)	(-50)
				(-50)	(-50)	(-50)	(-50)	(-50)	(-50)	(-50)	(-50)	(-50)	(-50)	(-50)	(-50)	(-50)	(-50)	(-50)	(-50)
				(-50)	(-50)	(-50)	(-50)	(-50)	(-50)	(-50)	(-50)	(-50)	(-50)	(-50)	(-50)	(-50)	(-50)	(-50)	(-50)
				(-50)	(-50)	(-50)	(-50)	(-50)	(-50)	(-50)	(-50)	(-50)	(-50)	(-50)	(-50)	(-50)	(-50)	(-50)	(-50)
				(-50)	(-50)	(-50)	(-50)	(-50)	(-50)	(-50)	(-50)	(-50)	(-50)	(-50)	(-50)	(-50)	(-50)	(-50)	(-50)
				(-50)	(-50)	(-50)	(-50)	(-50)	(-50)	(-50)	(-50)	(-50)	(-50)	(-50)	(-50)	(-50)	(-50)	(-50)	(-50)
				(-50)	(-50)	(-50)	(-50)	(-50)	(-50)	(-50)	(-50)	(-50)	(-50)	(-50)	(-50)	(-50)	(-50)	(-50)	(-50)
				(-50)	(-50)	(-50)	(-50)	(-50)	(-50)	(-50)	(-50)	(-50)	(-50)	(-50)	(-50)	(-50)	(-50)	(-50)	(-50)
				(-50)	(-50)	(-50)	(-50)	(-50)	(-50)	(-50)	(-50)	(-50)	(-50)	(-50)	(-50)	(-50)	(-50)	(-50)	(-50)
				(-50)	(-50)	(-50)	(-50)	(-50)	(-50)	(-50)	(-50)	(-50)	(-50)	(-50)	(-50)	(-50)	(-50)	(-50)	(-50)
				(-50)	(-50)	(-50)	(-50)	(-50)	(-50)	(-50)	(-50)	(-50)	(-50)	(-50)	(-50)	(-50)	(-50)	(-50)	(-50)
				(-50)	(-50)	(-50)	(-50)	(-50)	(-50)	(-50)	(-50)	(-50)	(-50)	(-50)	(-50)	(-50)	(-50)	(-50)	(-50)
				(-50)	(-50)	(-50)	(-50)	(-50)	(-50)	(-50)	(-50)	(-50)	(-50)	(-50)	(-50)	(-50)	(-50)	(-50)	(-50)
				(-50)	(-50)	(-50)	(-50)	(-50)	(-50)	(-50)	(-50)	(-50)	(-50)	(-50)	(-50)	(-50)	(-50)	(-50)	(-50)
				(-50)	(-50)	(-50)	(-50)	(-50)	(-50)	(-50)	(-50)	(-50)	(-50)	(-50)	(-50)	(-50)	(-50)	(-50)	(-50)
				(-50)	(-50)	(-50)	(-50)	(-50)	(-50)	(-50)	(-50)	(-50)	(-50)	(-50)	(-50)	(-50)	(-50)	(-50)	(-50)
				(-50)	(-50)	(-50)	(-50)	(-50)	(-50)	(-50)	(-50)	(-50)	(-50)	(-50)	(-50)	(-50)	(-50)	(-50)	(-50)
				(-50)	(-50)	(-50)	(-50)	(-50)	(-50)	(-50)	(-50)	(-50)	(-50)	(-50)	(-50)	(-50)	(-50)	(-50)	(-50)
				(-50)	(-50)	(-50)	(-50)	(-50)	(-50)	(-50)	(-50)	(-50)	(-50)	(-50)	(-50)	(-50)	(-50)	(-50)	(-50)
				(-50)	(-50)	(-50)	(-50)	(-50)	(-50)	(-50)	(-50)	(-50)	(-50)	(-50)	(-50)	(-50)	(-50)	(-50)	(-50)
				(-50)	(-50)	(-50)	(-50)	(-50)	(-50)	(-50)	(-50)	(-50)	(-50)	(-50)	(-50)	(-50)	(-50)	(-50)	(-50)
				(-50)	(-50)	(-50)	(-50)	(-50)	(-50)	(-50)	(-50)	(-50)	(-50)	(-50)	(-50)	(-50)	(-50)	(-50)	(-50)
				(-50)	(-50)	(-50)	(-50)	(-50)	(-50)	(-50)	(-50)	(-50)	(-50)	(-50)	(-50)	(-50)	(-50)	(-50)	(-50)
				(-50)	(-50)	(-50)	(-50)	(-50)	(-50)	(-50)	(-50)	(-50)	(-50)	(-50)	(-50)	(-50)	(-50)	(-50)	(-50)
				(-50)	(-50)	(-50)	(-50)	(-50)	(-50)	(-50)	(-50)	(-50)	(-50)	(-50)	(-50)	(-50)	(-50)	(-50)	(-50)
				(-50)	(-50)	(-50)	(-50)	(-50)	(-50)	(-50)	(-50)	(-50)	(-50)	(-50)	(-50)	(-50)	(-50)	(-50)	(-50)
				(-50)	(-50)	(-50)	(-50)	(-50)	(-50)	(-50)	(-50)	(-50)	(-50)	(-50)	(-50)	(-50)	(-50)	(-50)	(-50)
				(-50)	(-50)	(-50)	(-50)	(-50)	(-50)	(-50)	(-50)	(-50)	(-50)	(-50)	(-50)	(-50)	(-50)	(-50)	(-50)
				(-50)	(-50)	(-50)	(-50)	(-50)	(-50)	(-50)	(-50)	(-50)	(-50)	(-50)	(-50)	(-50)	(-50)	(-50)	(-50)
				(-50)	(-50)	(-50)	(-50)	(-50)	(-50)	(-50)	(-50)	(-50)	(-50)	(-50)	(-50)	(-50)	(-50)	(-50)	(-50)
				(-50)	(-50)	(-50)	(-50)	(-50)	(-50)	(-50)	(-50)	(-50)	(-50)	(-50)	(-50)	(-50)	(-50)	(-50)	(-50)
				(-50)	(-50)	(-50)	(-50)	(-50)	(-50)	(-50)	(-50)	(-50)	(-50)	(-50)	(-50)	(-50)	(-50)	(-50)	(-50)
				(-75) (-75) (-75)>;

			PS_Config_Diff_Test_Frame = <50>;
		};
	};
	
};

&thermal_zones {
	quiet-therm-step {
		status = "ok";
	};
};

